# PCIE0_CORE_DBN_CFG_PCIE_CORE register map
Vendor: Texas Instruments
Registers are 32-bit, read-write, reset 0x0 unless marked. A register's access mark holds for its fields unless they carry their own. Offsets are as the file gives them; [hi:lo] are bit positions; {n}, {i} and the like mark numbered series.

## PCIE0_CORE_DBN_CFG_PCIE_CORE (part 4 of 6)
0x11C CORE__DBN_CFG__PCIE_CORE_REG_i_hdr_log_0 ro — This is the first of a set of four registers used to capture the header of a TLP received by the Controller from the link upon detection of an uncorrectable error. When multiple bits are set in the Uncorrectable Error Status Register, the captured header corresponds the the error that was detected first, that is, the error pointed by the First Error Pointer. To prevent the captured header from being over-written before software is able to read it, this register is not updated while the status bit pointed to by the First Error Pointer in the Uncorrectable Error Status Register remains set. After the software clears this status bit, a subsequent error condition that sets any bit in the Uncorrectable Error Status Register will also cause the Header Log Registers to be updated. The doublewords of the TLP header are stored in the Header Log Registers with their bytes transposed. That is, the byte containing the Type/Format fields of the header is stored at bit positions 31:24 of the Header Log Register 0.
  [31:0] HD0 — First Dword of captured TLP header. STICKY.
0x120 CORE__DBN_CFG__PCIE_CORE_REG_i_hdr_log_1 ro — This register contains the second Dword of the captured TLP header. The bytes are stored in transposed order.
  [31:0] HD1 — Second Dword of captured TLP header. STICKY.
0x124 CORE__DBN_CFG__PCIE_CORE_REG_i_hdr_log_2 ro — This register contains the third Dword of the captured TLP header. The bytes are stored in transposed order.
  [31:0] HD2 — Third Dword of captured TLP header. STICKY.
0x128 CORE__DBN_CFG__PCIE_CORE_REG_i_hdr_log_3 ro — If the captured TLP header is 4 Dwords long, this register contains its fourth Dword. If the captured header is a 3-Dword header, this register is unused. The bytes of the Dword are stored in this register in transposed order.
  [31:0] HD3 — Fourth Dword of captured TLP header. STICKY.
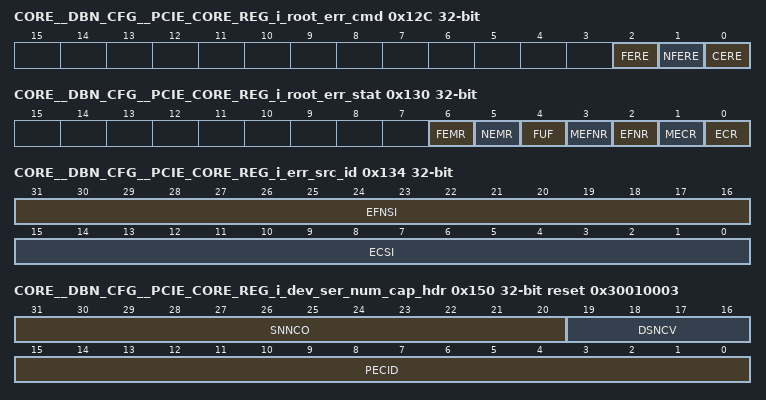
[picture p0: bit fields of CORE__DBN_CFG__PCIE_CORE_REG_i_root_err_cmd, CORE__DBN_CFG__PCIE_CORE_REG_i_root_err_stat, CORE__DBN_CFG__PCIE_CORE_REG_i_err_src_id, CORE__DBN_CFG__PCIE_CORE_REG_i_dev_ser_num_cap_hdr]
0x12C CORE__DBN_CFG__PCIE_CORE_REG_i_root_err_cmd — This register contains bits that control how the RC responds to errors reported by remote devices.
  [2] FERE — If this bit is set, the Controller will active its FATAL_ERROR_OUT output in response to an error message received from the link.
  [1] NFERE — If this bit is set, the Controller will active its NON_FATAL_ERROR_OUT output in response to an error message received from the link.
  [0] CERE — If this bit is set, the Controller will active its CORRECTABLE_ERROR_OUT output in response to an error message received from the link.
0x130 CORE__DBN_CFG__PCIE_CORE_REG_i_root_err_stat access not given — This register contains status information on error messages received from the link (that is, errors reported by remote devices attached to this Root Complex).
  [6] FEMR — This bit, when set, indicates that the RC has received one or more Fatal error messages from the link. STICKY (access R/W1TC)
  [5] NEMR — This bit, when set, indicates that the RC has received one or more Non-Fatal error messages from the link. STICKY (access R/W1TC)
  [4] FUF — This bit, when set, indicates that the first Uncorrectable error message received was for a Fatal error. STICKY (access R/W1TC)
  [3] MEFNR — This bit is set when the RC receives either a Fatal or Non-Fatal error message from the link, and the ERR_FATAL/NONFATAL Received bit is already set. STICKY (access R/W1TC)
  [2] EFNR — This bit is set when the RC receives either a Fatal or Non-Fatal error message from the link. STICKY (access R/W1TC)
  [1] MECR — This bit is set when the RC receives a Correctable error message from the link, if the ERR_COR received bit is already set. STICKY (access R/W1TC)
  [0] ECR — This bit is set when the RC receives a Correctable error message from the link. STICKY (access R/W1TC)
0x134 CORE__DBN_CFG__PCIE_CORE_REG_i_err_src_id ro — This register stores the Register IDs extracted from error messages received by the Root Complex from the link.
  [31:16] EFNSI — This field captures and stores the Requester ID from an ERR_FATAL or ERROR_NONFATAL message received by the RC, if the ERR_FATAL or NONFATAL Received bit was not set at the time the message was received. STICKY
  [15:0] ECSI — This field captures and stores the Requester ID from an ERR_COR message received by the RC, if the ERR_COR bit was not set at the time the message was received. STICKY
0x138 CORE__DBN_CFG__PCIE_CORE_REG_i_tlp_pre_log_0 ro — First TLP Prefix (if present) associated with the TLP whose header is in the Header Log Register. The bytes are in transposed order.
  [31:0] HD1 — First TLP Prefix of captured TLP STICKY.
0x150 CORE__DBN_CFG__PCIE_CORE_REG_i_dev_ser_num_cap_hdr ro reset 0x30010003 — This register contains the PCI Express Extended Capability ID for Device Serial Number Capability, the capability version, and the pointer to the next capability structure.
  [31:20] SNNCO — Indicates offset to the next PCI Express capability structure. The default next pointer value is dynamic and is dependent on whether the strap or LMI bits are set.
  [19:16] DSNCV — Specifies the SIG assigned value for the version of the capability structure. This field is set by default to 1, but can be modified from the local management bus by writing into Function 0 from the local management bus.
  [15:0] PECID — This field is hardwired to the Capability ID assigned by PCI SIG to the PCI Express Device Serial Number Capability [0001 hex].
0x154 CORE__DBN_CFG__PCIE_CORE_REG_i_dev_ser_num_0 ro — This read-only register stored the first 32 bits of the device's serial number.
  [31:0] DSND0 — This field contains the first 32 bits of the device's serial number. This field can be written from the APB bus by setting [21] bit high of the pcie_mgmt_APB_ADDR during a local management register write.
0x158 CORE__DBN_CFG__PCIE_CORE_REG_i_dev_ser_num_1 ro — This read-only register stored the last 32 bits of the device's serial number.
  [31:0] DSND1 — This field contains the last 32 bits of the device's serial number. This field can be written from the APB bus by setting [21] bit high of the pcie_mgmt_APB_ADDR during a local management register write.
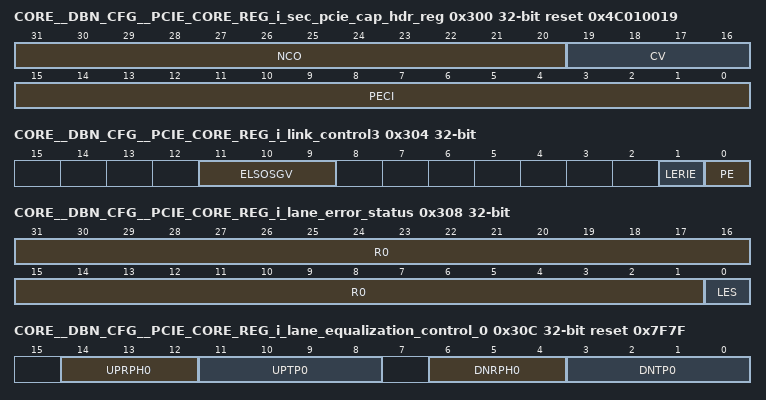
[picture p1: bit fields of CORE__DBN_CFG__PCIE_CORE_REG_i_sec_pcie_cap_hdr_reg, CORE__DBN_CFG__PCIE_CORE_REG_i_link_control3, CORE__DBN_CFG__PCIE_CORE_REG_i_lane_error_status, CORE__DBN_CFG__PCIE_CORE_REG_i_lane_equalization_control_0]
0x300 CORE__DBN_CFG__PCIE_CORE_REG_i_sec_pcie_cap_hdr_reg ro reset 0x4C010019 — This register contains the PCI Express Extended Capability ID for the Secondary PCI Express Extended Capability, its capability version, and the pointer to the next capability structure. This register is implemented only in the configuration space of PF 0 or RC.
  [31:20] NCO — Indicates offset to the next PCI Express capability structure. The default next pointer value is dynamic and is dependent on whether the strap or LMI bits are set.
  [19:16] CV — Specifies the SIG assigned value for the version of the capability structure. This field is set by default to 1 , but can be modified independently for each PF from [ the APB bus by setting [21] bit high of the pcie_mgmt_APB_ADDR during a local management register write] .
  [15:0] PECI — This field is hardwired to the Capability ID assigned by PCI SIG to the Secondary PCI Express Capability
0x304 CORE__DBN_CFG__PCIE_CORE_REG_i_link_control3 — This register is part of the Secondary PCI Express Extended Capability Structure. It contains bits to control the link equalization procedure at 8 GT/s speed.
  [11:9] ELSOSGV — When the Link is in L0 and the bit in this field corresponding to the current Link speed is Set, SKP Ordered Sets are scheduled at the rate defined for SRNS, overriding the rate required based on the clock tolerance architecture.
  [1] LERIE — This bit enables the activation of the LOCAL_INTERRUPT_OUT output of the Controller when the Link Equalization Request bit in the Link Status 2 Register Or the Link Equalization Request 16.0 GT/s in the 16GTs Status Register is set.
  [0] PE — The state of this bit determines whether the Controller performs link equalization when the link is retrained by the local software. If this bit is set to 1 when the local software sets the Link Retrain bit in the Link Control Register, and the target link speed is 8 GT/s, the LTSSM of the Controller will go through the link equalization states during the retraining.
0x308 CORE__DBN_CFG__PCIE_CORE_REG_i_lane_error_status access not given — This register contains one bit per lane indicating the physical-layer error status of the corresponding lane. A 1 indicates that a physical-layer error was detected by the Controller in the corresponding lane. The error can be cleared by writing a 1 into the bit position, either through a Configuration Write transaction from the link or from the local management APB bus.
  [31:1] R0 ro
  [0] LES — Each of these bits indicates the error status for the corresponding lane. STICKY. (access R/W1TC)
0x30C CORE__DBN_CFG__PCIE_CORE_REG_i_lane_equalization_control_0 ro reset 0x7F7F — This register contains the 8.0GT/s Transmitter Preset and the Receiver Preset Hint values for lanes 0 and 1, for use during the Link Equalization procedure.
  [14:12] UPRPH0 — 8.0GT/s Value sent by the Controller as the Receiver Preset Hint for the remote receiver associated with Lane 0. The remote node may use this value to adapt its receiver at the start of the link equalization procedure.
  [11:8] UPTP0 — 8.0GT/s Value sent by the Controller as the Transmitter Preset for the remote transmitter associated with Lane 0. The remote node uses this value to set up its transmitter at the start of the link equalization procedure.
  [6:4] DNRPH0 — 8.0GT/s Receiver Preset Hint value to be used for the local receiver associated with Lane 0. The Controller uses this value to set up the receiver attached to Lane 0
  [3:0] DNTP0 — 8.0GT/s Transmitter Preset value to be used for the local transmitter associated with Lane 0. The Controller uses this value to set up the Lane 0 transmitter during link equalization.
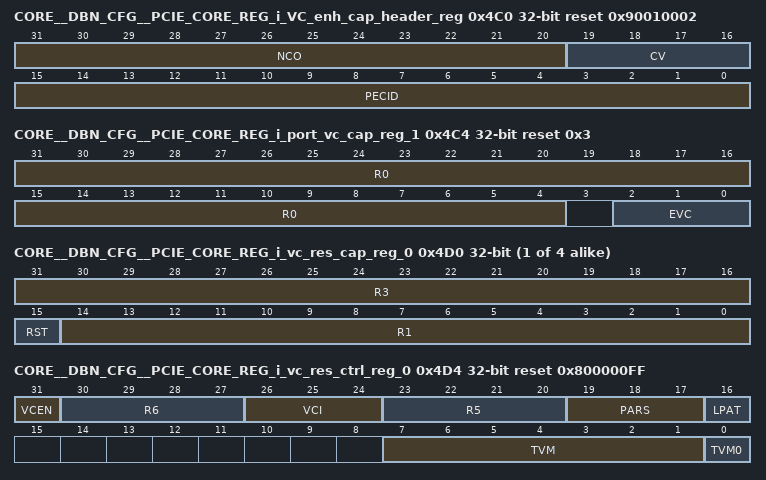
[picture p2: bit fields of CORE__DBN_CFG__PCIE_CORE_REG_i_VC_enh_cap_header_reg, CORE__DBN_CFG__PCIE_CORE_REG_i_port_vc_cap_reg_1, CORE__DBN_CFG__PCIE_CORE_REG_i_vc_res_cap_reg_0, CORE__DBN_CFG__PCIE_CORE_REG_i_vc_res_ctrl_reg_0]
0x4C0 CORE__DBN_CFG__PCIE_CORE_REG_i_VC_enh_cap_header_reg ro reset 0x90010002 — This is the first register in the Virtual Channel Capability Structure. The VC Capability is present only in the configuration space of Physical Function 0. This register contains the PCI Express Extended Capability ID, the capability version, and the pointer to the next capability structure.
  [31:20] NCO — Indicates offset to the next PCI Express capability structure. The default next pointer value is dynamic and is dependent on whether the strap or LMI bits are set.
  [19:16] CV — Specifies the SIG assigned value for the version of the capability structure. This field is set by default to 1, but can be modified independently for each PF from the local management bus.
  [15:0] PECID — This field is hardwired to the Capability ID assigned by PCI SIG to the VC Capability.
0x4C4 CORE__DBN_CFG__PCIE_CORE_REG_i_port_vc_cap_reg_1 ro reset 0x3 — This register has fields that describe the capabilities of the device with respect to the virtual channels.
  [31:4] R0, [2:0] EVC
0x4C8 CORE__DBN_CFG__PCIE_CORE_REG_i_port_vc_cap_reg_2 ro — This register has fields that describe the capabilities of the device with respect to the virtual channels. This register is not implemented. A read from this location returns all zeroes.
  [31:0] R1
0x4CC CORE__DBN_CFG__PCIE_CORE_REG_i_port_vc_ctrl_sts_reg ro — This location contains the 16-bit VC Control Register and the 16-bit VC Status Register. These registers are not implemented. A read from this location returns all zeroes.
  [31:0] R2
{0x4D0+0xC*i} CORE__DBN_CFG__PCIE_CORE_REG_i_vc_res_cap_reg_{i} ro (i=0..3) — This register describes the capabilities associated with VC {i}.
  [31:16] R3, [15] RST, [14:0] R1
0x4D4 CORE__DBN_CFG__PCIE_CORE_REG_i_vc_res_ctrl_reg_0 access per field reset 0x800000FF — This register contains bits to configure VC 0.
  [31] VCEN ro — Software uses this bit to enable the VC. For VC0 this bit is hardwired to 1.
  [30:27] R6 ro
  [26:24] VCI ro — VC ID assigned to VC0. For the VC0, this field is read-only and it is hardwired to 00b. For non VC0 case, it is allowed to use any VC-ID. This VC-ID has to be unique across all VCs. This must not be same as VC0's ID[VC0 ID=0].
  [23:20] R5 ro
  [19:17] PARS ro — Configures the VC to use a specific port arbitration scheme. This field is not implemented, and hardwired to 0.
  [16] LPAT ro — Updates the port arbitration logic from the Port Arbitration Table for VC 0. This bit is not implemented, and hardwired to 0.
  [7:1] TVM rw — Indicates the TCs that are mapped to this VC. When bit 0 of this field is set, it indicates that TC 0 is mapped to VC 0.By default, all TCs are mapped to VC 0.
  [0] TVM0 ro — Indicates the TC0 always mapped to VC0.
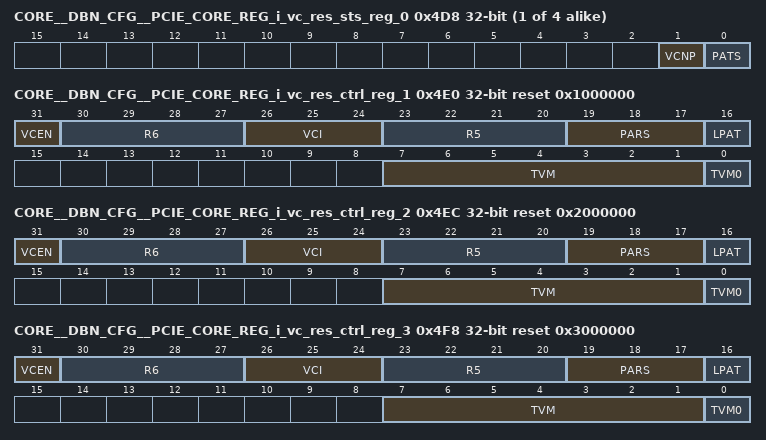
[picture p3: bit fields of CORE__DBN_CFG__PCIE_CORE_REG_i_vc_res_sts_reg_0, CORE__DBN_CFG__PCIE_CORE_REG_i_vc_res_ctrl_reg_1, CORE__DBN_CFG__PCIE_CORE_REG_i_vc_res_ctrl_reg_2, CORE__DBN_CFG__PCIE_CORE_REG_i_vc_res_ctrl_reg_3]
{0x4D8+0xC*i} CORE__DBN_CFG__PCIE_CORE_REG_i_vc_res_sts_reg_{i} ro (i=0..3) — This register contains status bits associated with VC {i}.
  [1] VCNP — This indicates whether the Virtual Channel negotiation is in pending state. The value of this bit is defined only when the link is in the DL_Active state and Virtual Channel is enabled. When this bit is set by hardware, it indicates that the VC resource has not completed the process of negotiation. This bit is cleared by hardware after the VC negotiation is complete.
  [0] PATS — This is not implemented and hardwired to 0.
0x4E0 CORE__DBN_CFG__PCIE_CORE_REG_i_vc_res_ctrl_reg_1 access per field reset 0x1000000 — This register contains bits to configure VC 1.
  [31] VCEN rw — Software uses this bit to enable the VC. For VC0 this bit is hardwired to 1.
  [30:27] R6 ro
  [26:24] VCI rw — VC ID assigned to VC1. For the VC0, this field is read-only and it is hardwired to 00b. For non VC0 case, it is allowed to use any VC-ID. This VC-ID has to be unique across all VCs. This must not be same as VC0's ID[VC0 ID=0].
  [23:20] R5 ro
  [19:17] PARS ro — Configures the VC to use a specific port arbitration scheme. This field is not implemented, and hardwired to 0.
  [16] LPAT ro — Updates the port arbitration logic from the Port Arbitration Table for VC 1. This bit is not implemented, and hardwired to 0.
  [7:1] TVM rw — Indicates the TCs that are mapped to this VC. When bit 1 of this field is set, it indicates that TC 1 is mapped to VC 1.By default, all TCs are mapped to VC 0.
  [0] TVM0 ro — Indicates the TC0 always mapped to VC0.
0x4EC CORE__DBN_CFG__PCIE_CORE_REG_i_vc_res_ctrl_reg_2 access per field reset 0x2000000 — This register contains bits to configure VC 2.
  [31] VCEN rw — Software uses this bit to enable the VC. For VC0 this bit is hardwired to 1.
  [30:27] R6 ro
  [26:24] VCI rw — VC ID assigned to VC2. For the VC0, this field is read-only and it is hardwired to 00b. For non VC0 case, it is allowed to use any VC-ID. This VC-ID has to be unique across all VCs. This must not be same as VC0's ID[VC0 ID=0].
  [23:20] R5 ro
  [19:17] PARS ro — Configures the VC to use a specific port arbitration scheme. This field is not implemented, and hardwired to 0.
  [16] LPAT ro — Updates the port arbitration logic from the Port Arbitration Table for VC 2. This bit is not implemented, and hardwired to 0.
  [7:1] TVM rw — Indicates the TCs that are mapped to this VC. When bit 2 of this field is set, it indicates that TC 2 is mapped to VC 2.By default, all TCs are mapped to VC 0.
  [0] TVM0 ro — Indicates the TC0 always mapped to VC0.
0x4F8 CORE__DBN_CFG__PCIE_CORE_REG_i_vc_res_ctrl_reg_3 access per field reset 0x3000000 — This register contains bits to configure VC 3.
  [31] VCEN rw — Software uses this bit to enable the VC. For VC0 this bit is hardwired to 1.
  [30:27] R6 ro
  [26:24] VCI rw — VC ID assigned to VC3. For the VC0, this field is read-only and it is hardwired to 00b. For non VC0 case, it is allowed to use any VC-ID. This VC-ID has to be unique across all VCs. This must not be same as VC0's ID[VC0 ID=0].
  [23:20] R5 ro
  [19:17] PARS ro — Configures the VC to use a specific port arbitration scheme. This field is not implemented, and hardwired to 0.
  [16] LPAT ro — Updates the port arbitration logic from the Port Arbitration Table for VC 3. This bit is not implemented, and hardwired to 0.
  [7:1] TVM rw — Indicates the TCs that are mapped to this VC. When bit 3 of this field is set, it indicates that TC 3 is mapped to VC 3.By default, all TCs are mapped to VC 0.
  [0] TVM0 ro — Indicates the TC0 always mapped to VC0.
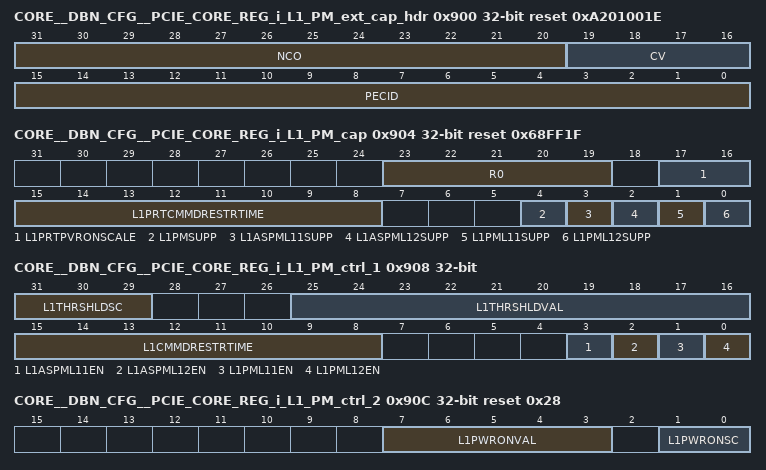
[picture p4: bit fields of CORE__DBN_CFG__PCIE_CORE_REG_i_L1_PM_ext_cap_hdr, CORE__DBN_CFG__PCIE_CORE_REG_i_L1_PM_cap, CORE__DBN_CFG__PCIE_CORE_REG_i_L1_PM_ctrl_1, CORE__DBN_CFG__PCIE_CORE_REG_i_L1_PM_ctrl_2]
0x900 CORE__DBN_CFG__PCIE_CORE_REG_i_L1_PM_ext_cap_hdr ro reset 0xA201001E — L1 PM Substates Extended Capability Header Register.
  [31:20] NCO — Indicates offset to the next PCI Express capability structure. The default next pointer value is dynamic and is dependent on whether the strap or LMI bits are set.
  [19:16] CV — Specifies the SIG assigned value for the version of the capability structure. This field is set by default to 1, but can be modified from the local management bus.
  [15:0] PECID — This field is hardwired to the Capability ID assigned by PCI SIG to the L1 PM Substates Extended Capability Structure [001E hex].
0x904 CORE__DBN_CFG__PCIE_CORE_REG_i_L1_PM_cap ro reset 0x68FF1F — This register advertises the L1 PM Substates Capabilities.
  [23:19] R0 — Along with the Port T_POWER_ON Scale field in the L1 PM Substates Capabilities register sets the time [in us] that this Port requires the port on the opposite side of Link to wait in L1.2.Exit after sampling CLKREQ# asserted before actively driving the interface. The value of Port T_POWER_ON is calculated by multiplying the value in this field by the scale value in the Port T_POWER_ON Scale field in the L1 PM Substates Capabilities register. T Power On is the minimum amount of time that each component must wait in L1.2.Exit after sampling CLKREQ# asserted before actively driving the interface. This is to ensure no device is ever actively driving into an unpowered component.
  [17:16] L1PRTPVRONSCALE — Specifies the scale used for the Port T_POWER_ON Value field in the L1 PM Substates Capabilities register. Range of Values 00b = 2us 01b = 10us 10b = 100us 11b = Reserved Default value is 00.
  [15:8] L1PRTCMMDRESTRTIME — Time [in us] required for this Port to re-establish common mode during exit from PM or ASPM L1.2 substate
  [4] L1PMSUPP — When Set this bit indicates that this Port supports L1 PM Substates.
  [3] L1ASPML11SUPP — When Set this bit indicates that ASPM L1.1 is supported.
  [2] L1ASPML12SUPP — When Set this bit indicates that ASPM L1.2 is supported.
  [1] L1PML11SUPP — When Set this bit indicates that PCI-PM L1.1 is supported.
  [0] L1PML12SUPP — When Set this bit indicates that PCI-PM L1.2 is supported.
0x908 CORE__DBN_CFG__PCIE_CORE_REG_i_L1_PM_ctrl_1 — L1 PM Substates Control 1 Register
  [31:29] L1THRSHLDSC — This field provides a scale for the value contained within the LTR_L1.2_THRESHOLD_Value. 000 - Value times 1 ns 001 - Value times 32 ns 010 - Value times 1024 ns 011 - Value times 32,768 ns 100 - Value times 1,048,576 ns 101 - Value times 33,554,422ns 110-111 - Not permitted
  [25:16] L1THRSHLDVAL — Along with the LTR_L1.2_THRESHOLD_Scale, this field indicates the LTR threshold used to determine if entry into L1 results in L1.1 [if enabled] or L1.2 [if enabled].
  [15:8] L1CMMDRESTRTIME — Sets value of TCOMMONMODE [in us], which must be used by the Downstream Port for timing the re-establishment of common mode. This field must only be modified when the ASPM L1.2 Enable and PCI-PM L1.2 Enable bits are both Clear. This field is reserved since both PCI-PM L1.2 and ASPM L1.2 are Not Supported in this configuration of the Controller.
  [3] L1ASPML11EN — When Set this bit enables ASPM L1.1.
  [2] L1ASPML12EN — When Set this bit enables ASPM L1.2.
  [1] L1PML11EN — When Set this bit enables PCI-PM L1.1.
  [0] L1PML12EN — When Set this bit enables PCI-PM L1.2.
0x90C CORE__DBN_CFG__PCIE_CORE_REG_i_L1_PM_ctrl_2 reset 0x28 — L1 PM Substates Control 2 Register
  [7:3] L1PWRONVAL — Along with the T_POWER_ON Scale sets the minimum amount of time [in us] that the Port must wait in L1.2.Exit after sampling CLKREQ# asserted before actively driving the interface. T_POWER_ON is calculated by multiplying the value in this field by the value in the T_POWER_ON Scale field.
  [1:0] L1PWRONSC — Specifies the scale used for T_POWER_ON Value. Range of Values 00b = 2us 01b = 10us 10b = 100us 11b = Reserved
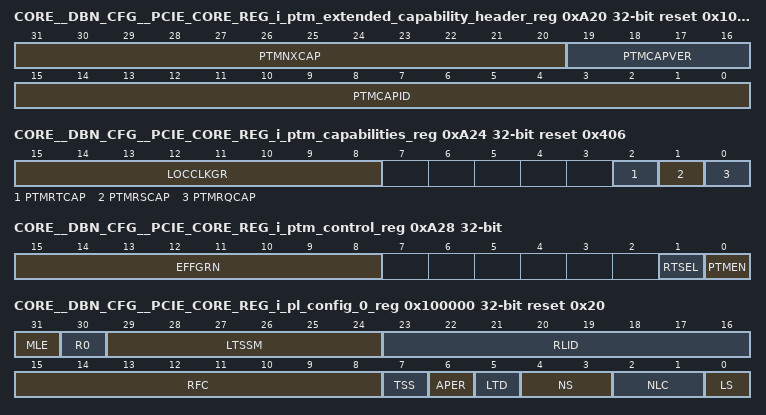
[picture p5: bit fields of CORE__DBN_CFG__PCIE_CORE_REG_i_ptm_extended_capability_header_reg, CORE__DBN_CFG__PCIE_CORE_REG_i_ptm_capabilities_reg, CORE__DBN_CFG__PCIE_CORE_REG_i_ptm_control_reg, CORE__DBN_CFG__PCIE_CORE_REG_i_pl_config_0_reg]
0xA20 CORE__DBN_CFG__PCIE_CORE_REG_i_ptm_extended_capability_header_reg ro reset 0x1001F — Precision Time Measurement Extended Capability Structure is used discovering and controlling the distribution of a PTM hierarchy.
  [31:20] PTMNXCAP — The offset to the next PCIe Extended Capability structure.
  [19:16] PTMCAPVER — This field is a PCI-SIG defined version number that indicates the version of the Capability structure present.
  [15:0] PTMCAPID — Indicates that the associated extended capability structure is for Precision Time Measurement capability. This field returns a Capability ID of 001Fh.
0xA24 CORE__DBN_CFG__PCIE_CORE_REG_i_ptm_capabilities_reg ro reset 0x406 — PTM Capabilities Register.
  [15:8] LOCCLKGR — In RC Mode: The Controller uses the CORE_CLK as the Local Clock for PTM. This field is used to indicate the Time Period of the CORE_CLK. If the PTM Root Select is 1, then CORE_CLK is used to provide PTM Master Time. If the PTM Root Select is 0, then CORE_CLK is used to locally track the PTM Master Time received on the PTM_LOCAL_TIMER_IN[63:0] input. By default, this field is set to 8'd4. This bit can be programmed through the local management APB interface if required.
  [2] PTMRTCAP — This bit is used to indicate that the Controller implements PTM Time Source Role and is capable of serving as PTM Root. By default, this bit is set to 1 when the Controller is in RC Mode. This bit can be programmed through the local management APB interface if required. Note: If this bit is programmed to 1, then the PTM Responder Capable bit must also be programmed to 1 by FW.
  [1] PTMRSCAP — This bit is used to indicate support for PTM Responder Role. By default, this bit is set to 1 when the Controller is in RC Mode. This bit can be programmed through the local management APB interface if required. Note: If the PTM Root Capable is programmed to 1, then this bit must also be programmed to 1 by FW.
  [0] PTMRQCAP — This bit is used to indicate support for PTM Requester Role. By default, this bit is set to 0 when the Controller is in RC Mode. This bit can be programmed through the local management APB interface if required.
0xA28 CORE__DBN_CFG__PCIE_CORE_REG_i_ptm_control_reg access per field — PTM Control Register.
  [15:8] EFFGRN ro — This field is used only in PTM Requester Mode and is not used in RC Mode. This field is set to 00 by default in RC Mode.
  [1] RTSEL rw — This field is configured by System SW. When set to 1 and when PTM Enable bit is aslo set to 1, this PTM Source is the PTM Root. Default value of this bit is 0.
  [0] PTMEN rw — When Set, this function is permitted to participate in the PTM mechanism as PTM Requester. By default, this bit is set to 0.
0x100000 CORE__DBN_CFG__PCIE_CORE_REG_i_pl_config_0_reg access per field reset 0x20 — This register contains the configured parameters at the Physical Layer of the link, and status information from the Physical Layer.
  [31] MLE rw — When the Controller is operating as a Root Port, setting this to 1 causes the LTSSM to initiate a loopback and become the loopback master. This bit is not used in the EndPoint Mode.
  [30] R0 ro — A 1 in this field indicates that the remote node advertised Linkwidth Upconfigure Capability in the training sequences in the Configuration.Complete state when the link came up. A 0 indicates that the remote node did not set the Link Upconfigure bit.
  [29:24] LTSSM ro — Current state of the LTSSM. The encoding of the states is given in Appendix C.
  [23:16] RLID ro — Link ID received from other side during link training.
  [15:8] RFC ro — FTS count received from the other side during link training for use at the 2.5 GT/s link speed. The Controller transmits this many FTS sequences while exiting the L0S state, when operating at the 2.5 GT/s speed.
  [7] TSS rw — This bit drives the PIPE_TX_SWING output of the Controller.
  [6] APER rw — This bit controls the reporting of Errors Detected by the PHY. The Errors Detected by the PHY include:- - Received errors indicated on PIPE RxStatus interface, - 8.0 GT/s Invalid Sync Header received error, If PHY Error Reporting bit is set to 0, the Controller will only report those errors that caused a TLP or DLLP to be dropped because of a Detected PHY Error. If PHY Error Reporting bit is set to 1, the Controller will report all Detected PHY Errors regardless of whether a TLP or DLLP was dropped. The following registers report PHY error in conjunction with this bit: - Correctable Error Status Register, i_corr_err_status, bit-0, Receiver Error Status - Local Error and Status Register, i_local_error_status_register, bit-7, Phy Error In addition to the Errors Detected by the PHY[PCS], the Controller detects the following Physical Layer Protocol Framing Errors: - Framing Errors in the received DLLP and TLP - Ordered Set Block Received Without EDS - Data Block Received After EDS - Illegal Ordered Set Block Received After EDS - Ordered Set Block Received After Skip OS Note: These Errors are always reported independent of the setting of this bit.
  [5] LTD ro — The state of this bit indicates whether the Controller completed link training as an upstream port[EndPoint][=0] or a downstream port[Root Port][=1]. Default value depends on CORE_TYPE strap pin.
  [4:3] NS ro — Current operating speed of link [00 = 2.5G, 01 = 5G, 10 = 8G, 11 = 16G].
  [2:1] NLC ro
  [0] LS ro — Current state of link [1 = link training complete, 0 = link training not complete].
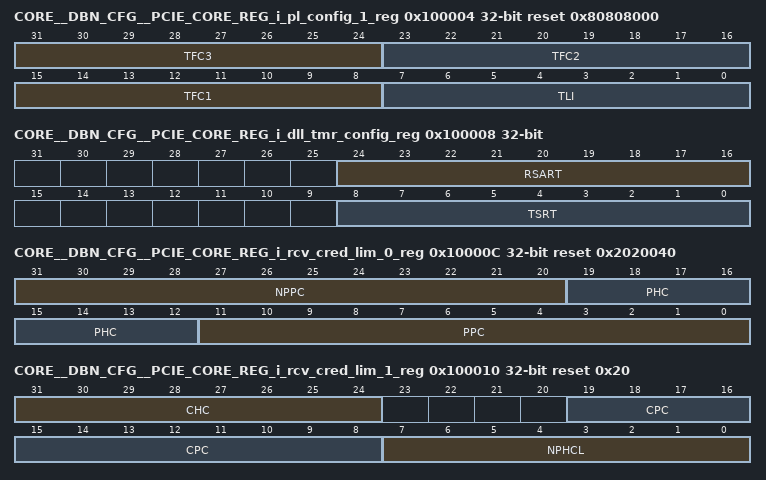
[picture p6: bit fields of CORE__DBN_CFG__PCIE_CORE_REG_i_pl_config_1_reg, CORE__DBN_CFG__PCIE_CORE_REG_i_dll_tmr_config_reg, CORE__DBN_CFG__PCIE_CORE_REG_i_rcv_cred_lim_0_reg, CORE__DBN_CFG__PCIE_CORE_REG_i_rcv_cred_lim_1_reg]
0x100004 CORE__DBN_CFG__PCIE_CORE_REG_i_pl_config_1_reg reset 0x80808000 — This register contains additional configured parameters at the Physical Layer of the link, and command bits for various Physical Layer functions.
  [31:24] TFC3 — FTS count transmitted by the Controller in TS1/TS2 sequences during link training. This value must be set based on the time needed by the receiver to acquire sync while exiting from L0S state.
  [23:16] TFC2 — FTS count transmitted by the Controller in TS1/TS2 sequences during link training. This value must be set based on the time needed by the receiver to acquire sync while exiting from L0S state.
  [15:8] TFC1 — FTS count transmitted by the Controller in TS1/TS2 sequences during link training. This value must be set based on the time needed by the receiver to acquire sync while exiting from L0S state.
  [7:0] TLI — Link ID transmitted by the device in training sequences in the Root Port mode.
0x100008 CORE__DBN_CFG__PCIE_CORE_REG_i_dll_tmr_config_reg — This register defines the replay timeout values used by the DL receive and transmit sides of the link. It can be read or written via the local management APB bus.
  [24:16] RSART — Additional receive side ACK-NAK timer timeout interval. This 9-bit value is added as a signed 2's complement number to the internal ACK-NAK timer timeout value computed by the Controller based on the PCI Express Specifications. This enables the user to make minor adjustments to the spec-defined replay timer settings.Its value is in multiples of [2 Symbol Times] At Gen1 adjustment range = [+2040 ns to -2048 ns]. At Gen2 adjustment range = [+1020 ns to -1024 ns]. At Gen3 adjustment range = [+510 ns to -512 ns].
  [8:0] TSRT — Additional transmit-side replay timer timeout interval. This 9-bit value is added as a signed 2's complement number to the internal replay timer timeout value computed by the Controller based on the PCI Express Specifications. This enables the user to make minor adjustments to the spec-defined replay timer settings. Its value is in multiples of [2 Symbol Times] At Gen1 adjustment range = [+2040 ns to -2048 ns]. At Gen2 adjustment range = [+1020 ns to -1024 ns]. At Gen3 adjustment range = [+510 ns to -512 ns].
0x10000C CORE__DBN_CFG__PCIE_CORE_REG_i_rcv_cred_lim_0_reg reset 0x2020040 — This register contains the initial credit limits advertised by the Controller during th DL initialization. If the fields of this register are modified, the link must be re-trained to re-initialize the DL for the modified settings to take effect. The credit limit fields in this register can be programmed to any value lesser than or equal to the respective default values. The default values are set to advertise the full size of the receive buffers. If a value of 0x00 is programmed, it implies infinite credit. Note: This may result in receiver overflow if received data is back pressured on the Client interface.
  [31:20] NPPC — Non-Posted payload credit limit advertised by the Controller for VC 0 . [in units of 4 Dwords] Caution: The programmed Header and Payload credit values must not exceed the actual size of the Receive Buffer.
  [19:12] PHC — Posted header credit limit advertised by the Controller for VC 0. [in units of 1 Packet Header] Note: Packet Header represents one maximum-size TLP Header + TLP Digest + maximum number of EndEnd TLP Prefixes permitted in a TLP. Caution: The programmed Header and Payload credit values must not exceed the actual size of the Receive Buffer.
  [11:0] PPC — Posted payload credit limit advertised by the Controller for VC 0. [in units of 4 Dwords] Caution: The programmed Header and Payload credit values must not exceed the actual size of the Receive Buffer.
0x100010 CORE__DBN_CFG__PCIE_CORE_REG_i_rcv_cred_lim_1_reg reset 0x20 — This register contains the initial credit limits advertised by the Controller during the DL initialization. If the fields of this register are modified, the link must be re-trained to re-initialize the DL for the modified settings to take effect. The credit limit fields in this register can be programmed to any value lesser than or equal to the respective default values. The default values are set to advertise the full size of the receive buffers. If a value of 0x00 is programmed, it implies infinite credit. Note: This may result in receiver overflow if received data is back pressured on the Client interface.
  [31:24] CHC — Completion header credit limit advertised by the Controller for VC 0 [in number of packets]. [in units of 1 Packet Header] Note: Packet Header represents one maximum-size TLP Header + TLP Digest + maximum number of EndEnd TLP Prefixes permitted in a TLP. Caution: The programmed Header and Payload credit values must not exceed the actual size of the Receive Buffer.
  [19:8] CPC — Completion payload credit limit advertised by the Controller for VC 0 . [in units of 4 Dwords] Caution: The programmed Header and Payload credit values must not exceed the actual size of the Receive Buffer.
  [7:0] NPHCL — Non-Posted header credit limit advertised by the Controller for VC 0 [in number of packets]. [in units of 1 Packet Header] Note: Packet Header represents one maximum-size TLP Header + TLP Digest + maximum number of EndEnd TLP Prefixes permitted in a TLP. Caution: The programmed Header and Payload credit values must not exceed the actual size of the Receive Buffer.
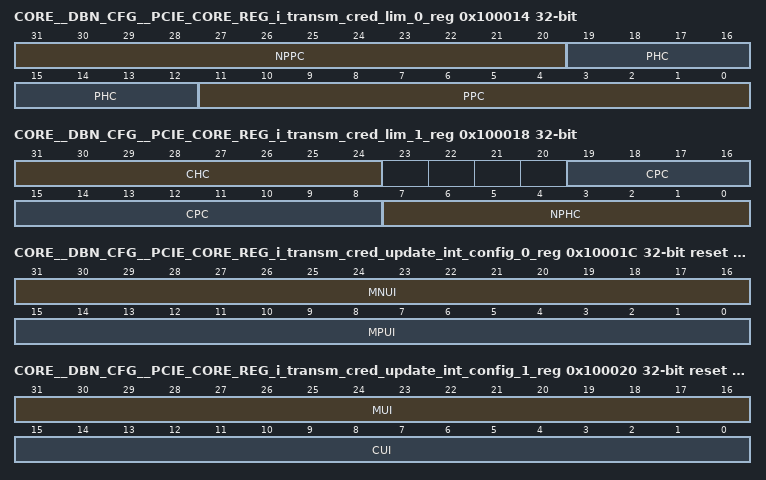
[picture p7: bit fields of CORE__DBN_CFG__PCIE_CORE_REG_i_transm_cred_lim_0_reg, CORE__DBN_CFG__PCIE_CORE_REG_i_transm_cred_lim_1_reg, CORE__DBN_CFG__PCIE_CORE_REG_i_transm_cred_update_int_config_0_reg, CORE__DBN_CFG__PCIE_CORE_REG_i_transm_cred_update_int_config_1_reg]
0x100014 CORE__DBN_CFG__PCIE_CORE_REG_i_transm_cred_lim_0_reg ro — This register contains the initial credit limits received from the opposite node during the DL initialization. It is a read-only register.
  [31:20] NPPC — Non-Posted payload credit limit received by the Controller for Link 0 . [in units of 4 Dwords]
  [19:12] PHC — Posted header credit limit received by the Controller for this link . [in units of 1 Packet Header] Note: Packet Header represents one maximum-size TLP Header + TLP Digest + maximum number of EndEnd TLP Prefixes permitted in a TLP.
  [11:0] PPC — Posted payload credit limit received by the Controller for this link . [in units of 4 Dwords]
0x100018 CORE__DBN_CFG__PCIE_CORE_REG_i_transm_cred_lim_1_reg ro — This register contains the initial credit limits received from the opposite node during the DL initialization. It is a read-only register.
  [31:24] CHC — Completion header credit limit received by the Controller for VC 0 . [in units of 1 Packet Header] Note: Packet Header represents one maximum-size TLP Header + TLP Digest + maximum number of EndEnd TLP Prefixes permitted in a TLP.
  [19:8] CPC — Completion payload credit limit received by the Controller for VC 0 . [in units of 4 Dwords]
  [7:0] NPHC — Non-Posted header credit limit received by the Controller for VC 0 . [in units of 1 Packet Header] Note: Packet Header represents one maximum-size TLP Header + TLP Digest + maximum number of EndEnd TLP Prefixes permitted in a TLP.
0x10001C CORE__DBN_CFG__PCIE_CORE_REG_i_transm_cred_update_int_config_0_reg reset 0x40004 — This register contains parameters that control how frequently the Controller sends a credit update to the opposite node.
  [31:16] MNUI — Minimum credit update interval for non-posted transactions. The Controller follows this minimum interval between issuing posted credit updates on the link. This is to limit the bandwidth use of credit updates. If new credit becomes available in the receive FIFO since the last update was sent, the Controller will issue a new update only after this interval has elapsed since the last update. The value is in units of 16 ns. This field is re-written by the internal logic when the negotiated link width or link speed changes, to correspond to the default values defined in defines.h. The user may override this default value by writing into this register field. The value written will be lost on a change in the negotiated link width/speed.
  [15:0] MPUI — Minimum credit update interval for posted transactions. The Controller follows this minimum interval between issuing posted credit updates on the link. This is to limit the bandwidth use of credit updates. If new credit becomes available in the receive FIFO since the last update was sent, the Controller will issue a new update only after this interval has elapsed since the last update. The value is in units of 16 ns. This field is re-written by the internal logic when the negotiated link width or link speed changes, to correspond to the default values defined in defines.h. The user may override this default value by writing into this register field. The value written will be lost on a change in the negotiated link width/speed.
0x100020 CORE__DBN_CFG__PCIE_CORE_REG_i_transm_cred_update_int_config_1_reg reset 0x3AA0004 — This register contains parameters that control how frequently the Controller sends a credit update to the opposite node.
  [31:16] MUI — Maximum credit update interval for all transactions. If no new credit has become available since the last update, the Controller will repeat the last update after this interval. This is to recover from any losses of credit update packets. The value is in units of 16 ns. This field could be re-written by the internal logic when the negotiated link width or link speed changes, to correspond to the default values defined in defines.h. The user may override this default value by writing into this register field. The value written will be lost on a change in the negotiated link width/speed.
  [15:0] CUI — Minimum credit update interval for Completion packets. The Controller follows this minimum interval between issuing completion credit updates on the link. This is to limit the bandwidth use of credit updates. If new credit becomes available in the receive FIFO since the last update was sent, the Controller will issue a new update only after this interval has elapsed since the last update. The value is in units of 16 ns. This parameter is not used when the Completion credit is infinity.
0x100024 CORE__DBN_CFG__PCIE_CORE_REG_i_L0S_timeout_limit_reg reset 0x177 — This register defines the timeout value for transitioning to the L0S power state. If the transmit side has been idle for this interval, the Controller will transmit the idle sequence on the link and transition the state of the link to L0S .
  [15:0] LT — Contains the timeout value [in units of 16 ns] for transitioning to the L0S power state. Setting this parameter to 0 permanently disables the transition to the L0S power state.
0x100028 CORE__DBN_CFG__PCIE_CORE_REG_i_transmit_tlp_count_reg access not given — This register contains the number of Transaction-Layer packets transmitted by the Controller on the link since the register was last reset. This counter saturates on reaching a count of all 1's. Writing all 1's to this register causes it to be reset to 0.
  [31:0] TTC — Count of TLPs transmitted (access R/W1TC)
0x10002C CORE__DBN_CFG__PCIE_CORE_REG_i_transmit_tlp_payload_dword_count_reg access not given — This register contains the aggregate number of payload double-words transmitted in Transaction-Layer Packets by the Controller on the link since the register was last reset. This counter saturates on reaching a count of all 1's. Writing all 1's to this register causes it to be reset to 0.
  [31:0] TTPBC — Count of TLPs payload Dwords transmitted (access R/W1TC)
0x100030 CORE__DBN_CFG__PCIE_CORE_REG_i_receive_tlp_count_reg access not given — This register contains the number of Transaction-Layer packets received by the Controller from the link since the register was last reset. This counter saturates on reaching a count of all 1's. Writing all 1's to this register causes it to be reset to 0.
  [31:0] RTC — Count of TLPs received (access R/W1TC)
0x100034 CORE__DBN_CFG__PCIE_CORE_REG_i_receive_tlp_payload_dword_count_reg access not given — This register contains the aggregate number of payload double-words received in Transaction-Layer packets by the Controller from the link since the register was last reset. This counter saturates on reaching a count of all 1's. Writing all 1's to this register causes it to be reset to 0.
  [31:0] RTPDC — Count of TLP payload Dwords received (access R/W1TC)
0x100038 CORE__DBN_CFG__PCIE_CORE_REG_i_compln_tmout_lim_0_reg reset 0xBEBC20 — This register contains the timeout value used to detect a completion timeout event for a request originated by the Controller from it master interface, when sub-range 1 is programmed in the Device Control 2 Register.
  [23:0] CTL — Timeout limit for completion timers [in 4 ns cycles]. Default value is 50 ms in 4 ns cycles. Please note that there could be a variation of 0 to +8us on the programmed Completion Timeout.
0x10003C CORE__DBN_CFG__PCIE_CORE_REG_i_compln_tmout_lim_1_reg reset 0x2FAF080 — This register contains the timeout value used to detect a completion timeout event for a request originated by the Controller from its master interface, when sub-range 2 is programmed in the Device Control 2 Register.
  [27:0] CTL — Timeout limit for completion timers [in 4 ns cycles]. Default value is 200ms in 4ns cycles. Please note that there could be a variation of 0 to +8us on the programmed Completion Timeout.
0x100040 CORE__DBN_CFG__PCIE_CORE_REG_i_L1_st_reentry_delay_reg — This register specifies the time the Controller will wait before it re-enters the L1 state if its link partner transitions the link to L0 while all the Functions of the Controller are in D3 power state. The Controller will change the power state of the link from L0 to L1 if no activity is detected both on the transmit and receive sides before this interval, while all Functions are in D3 state and the link is in L0. Setting this register to 0 disables re-entry to L1 state if the link partner returns the link to L0 from L1 when all the Functions of the Controller are in D3 state. This register controls only the re-entry to L1. The initial transition to L1 always occurs when all of the Functions of the Controller are set to the D3 state.
  [31:0] L1RD — Delay to re-enter L1 after no activity [in units of 16 ns].
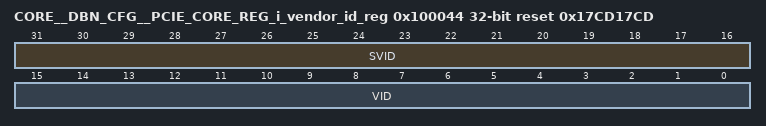
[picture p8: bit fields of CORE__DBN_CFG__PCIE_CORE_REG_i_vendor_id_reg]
0x100044 CORE__DBN_CFG__PCIE_CORE_REG_i_vendor_id_reg reset 0x17CD17CD — This register contains the Vendor ID and Subsystem Vendor ID that the device advertises during its enumeration of the PCI configuration space.
  [31:16] SVID — Subsystem Vendor ID
  [15:0] VID — Vendor ID
